# MCXN947_cm33_core0 register map
Vendor: nxp.com; File version: 1.0
CPU: CM33 r2p0, little endian, MPU, FPU, VTOR, 3 interrupt priority bits
Registers are 32-bit, read-write, reset 0x0 unless marked. A register's access mark holds for its fields unless they carry their own. Offsets are from the block's base; [hi:lo] are bit positions; lines under a group give offsets from that group; {n}, {i} and the like mark numbered series.

## SCT0 — SCT
Base 0x40091000
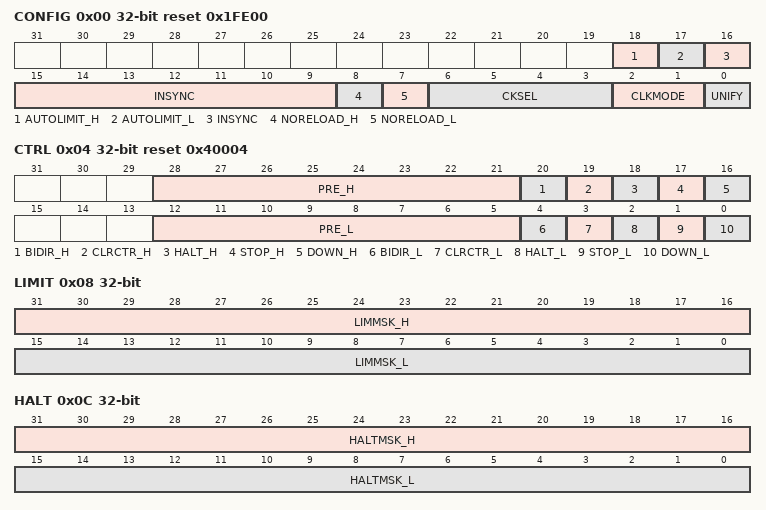
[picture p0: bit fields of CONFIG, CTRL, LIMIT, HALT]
0x00 CONFIG reset 0x1FE00 — SCT Configuration
  [18] AUTOLIMIT_H — Auto Limit Higher
    0=DISABLE (Disables); 1=ENABLE (Enables)
  [17] AUTOLIMIT_L — Auto Limit Lower
    0=DISABLE (Disables); 1=ENABLE (Enables)
  [16:9] INSYNC — Input Synchronization
  [8] NORELOAD_H — No Reload Higher Match
    0=RELOAD_H (Reloaded); 1=NO_RELOAD_H (Not reloaded)
  [7] NORELOAD_L — No Reload Lower Match
    0=RELOAD (Reloaded); 1=NO_RELOAD (Not reloaded)
  [6:3] CKSEL — SCT Clock Select
    0=INPUT_0_RISING_EDGES (Rising edges on input 0); 1=INPUT_0_FALLING_EDGES (Falling edges on input 0); 2=INPUT_1_RISING_EDGES (Rising edges on input 1); 3=INPUT_1_FALLING_EDGES (Falling edges on input 1); 4=INPUT_2_RISING_EDGES (Rising edges on input 2); 5=INPUT_2_FALLING_EDGES (Falling edges on input 2); 6=INPUT_3_RISING_EDGES (Rising edges on input 3); 7=INPUT_3_FALLING_EDGES (Falling edges on input 3); 8=INPUT_4_RISING_EDGES (Rising edges on input 4); 9=INPUT_4_FALLING_EDGES (Falling edges on input 4); 10=INPUT_5_RISING_EDGES (Rising edges on input 5); 11=INPUT_5_FALLING_EDGES (Falling edges on input 5); 12=INPUT_6_RISING_EDGES (Rising edges on input 6); 13=INPUT_6_FALLING_EDGES (Falling edges on input 6); 14=INPUT_7_RISING_EDGES (Rising edges on input 7); 15=INPUT_7_FALLING_EDGES (Falling edges on input 7)
  [2:1] CLKMODE — SCT Clock Mode
    0=SYSTEM_CLOCK_MODE; 1=SAMPLED_SYSTEM_CLOCK_MODE; 2=SCT_INPUT_CLOCK_MODE; 3=ASYNCHRONOUS_MODE
  [0] UNIFY — SCT Operation
    0=DUAL_COUNTER (Dual counters, COUNTER_L and COUNTER_H); 1=UNIFIED_COUNTER
0x04 CTRL reset 0x40004 — SCT Control
  [28:21] PRE_H — Prescaler for High Counter
  [20] BIDIR_H — Bidirectional Select High
    0=UP; 1=UP_DOWN
  [19] CLRCTR_H — Clear Counter High
  [18] HALT_H — Halt Counter High
    0=DISABLE; 1=ENABLE
  [17] STOP_H — Stop Counter High
    0=DISABLE (Disabled); 1=ENABLE (Enabled)
  [16] DOWN_H — Down Counter High
    0=UP; 1=DOWN
  [12:5] PRE_L — Prescaler for Low Counter
  [4] BIDIR_L — Bidirectional Select Low
    0=UP; 1=UP_DOWN
  [3] CLRCTR_L — Clear Counter Low
  [2] HALT_L — Halt Counter Low
    0=DISABLE (Disabled); 1=ENABLE (Enabled)
  [1] STOP_L — Stop Counter Low
    0=DISABLE (Disabled); 1=ENABLE (Enabled)
  [0] DOWN_L — Down Counter Low
    0=UP; 1=DOWN
0x08 LIMIT — SCT Limit Event Select
  [31:16] LIMMSK_H — Limit Event Counter High
  [15:0] LIMMSK_L — Limit Event Counter Low
0x0C HALT — Halt Event Select
  [31:16] HALTMSK_H — Halt Event High
  [15:0] HALTMSK_L — Halt Event Low
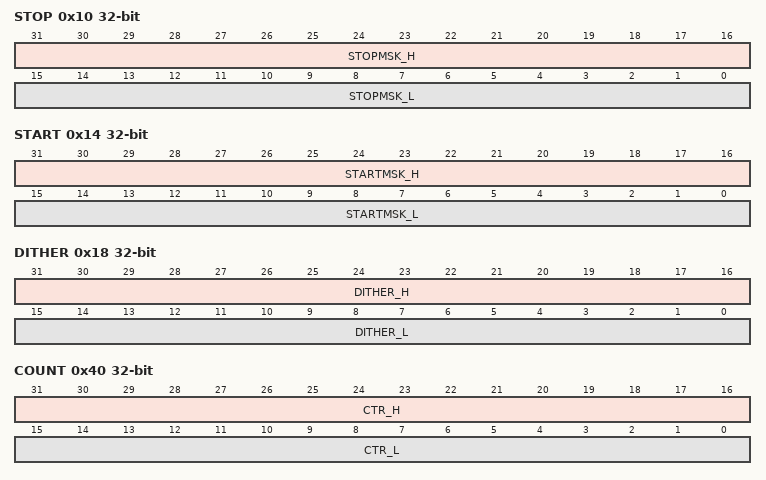
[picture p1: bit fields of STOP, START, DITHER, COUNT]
0x10 STOP — Stop Event Select
  [31:16] STOPMSK_H — Stop Event High
  [15:0] STOPMSK_L — Stop Event Low
0x14 START — Start Event Select
  [31:16] STARTMSK_H — Start Event High
  [15:0] STARTMSK_L — Start Event Low
0x18 DITHER — Dither Condition
  [31:16] DITHER_H — Dither High
  [15:0] DITHER_L — Dither Low
0x40 COUNT — Counter Value
  [31:16] CTR_H — Counter High
  [15:0] CTR_L — Counter Low
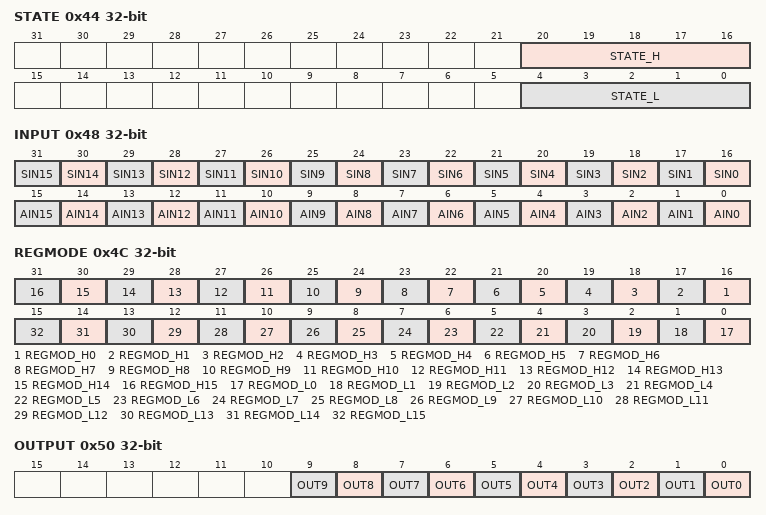
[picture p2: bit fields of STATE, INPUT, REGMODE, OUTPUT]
0x44 STATE — State Variable
  [20:16] STATE_H — State Variable High
  [4:0] STATE_L — State Variable Low
0x48 INPUT ro — Input State
  [n+16] SIN{n} (n=0..15) — Input {n} state
  [n] AIN{n} (n=0..15) — Input {n} state
0x4C REGMODE — Match and Capture Register Mode
  [all] fields
    0=MATCH; 1=CAPTURE
  [n+16] REGMOD_H{n} (n=0..15) — Register Mode High
  [n] REGMOD_L{n} (n=0..15) — Register Mode Low
0x50 OUTPUT — Output State
  [all] fields
    0=LOW (Forces the corresponding output low); 1=HIGH (Forces the corresponding output high)
  [n] OUT{n} (n=0..9) — Output Low and High
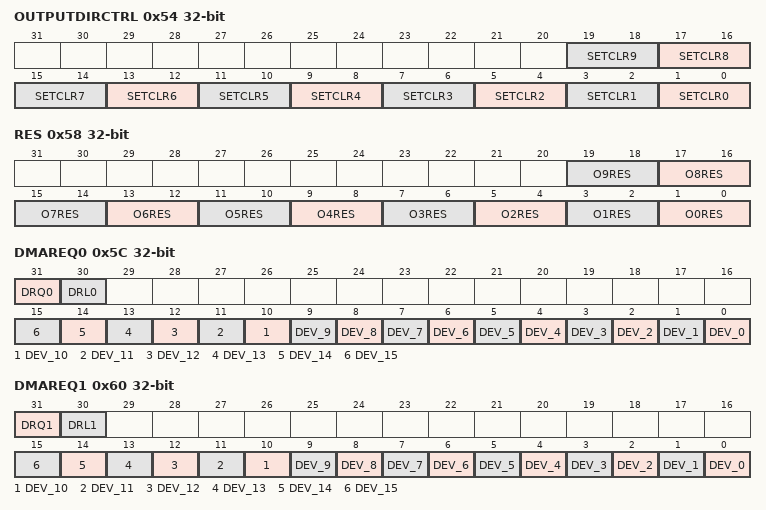
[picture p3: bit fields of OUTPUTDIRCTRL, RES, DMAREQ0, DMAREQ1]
0x54 OUTPUTDIRCTRL — Output Counter Direction Control
  [all] fields
    0=INDEPENDENT (Not dependent on the direction of any counter); 1=L_REVERSED (Reversed when counter L or the unified counter is counting down); 2=H_REVERSED (Reversed when counter H is counting down (do not use this value when CONFIG[UNIFY] = 1))
  [2n+1:2n] SETCLR{n} (n=0..9) — Set and Clear Operation on Output
0x58 RES — Output Conflict Resolution
  [all] fields
    0=NO_CHANGE; 1=SET (Set output (or clear, based on OUTPUTDIRCTRL[SETCLRn])); 2=CLEAR (Clear output (or set, based on OUTPUTDIRCTRL[SETCLRn])); 3=TOGGLE_OUTPUT
  [2n+1:2n] O{n}RES (n=0..9) — Output Resolution
0x5C DMAREQ0 — DMA Request 0
  [31] DRQ0 ro — DMA Request 0 State
  [30] DRL0 — DMA Request Low 0
  [n] DEV_{n} (n=0..15) — DMA Request Event
0x60 DMAREQ1 — DMA Request 1
  [31] DRQ1 ro — DMA Request 1 State
  [30] DRL1 — DMA Request Low 1
  [n] DEV_{n} (n=0..15) — DMA Request Event
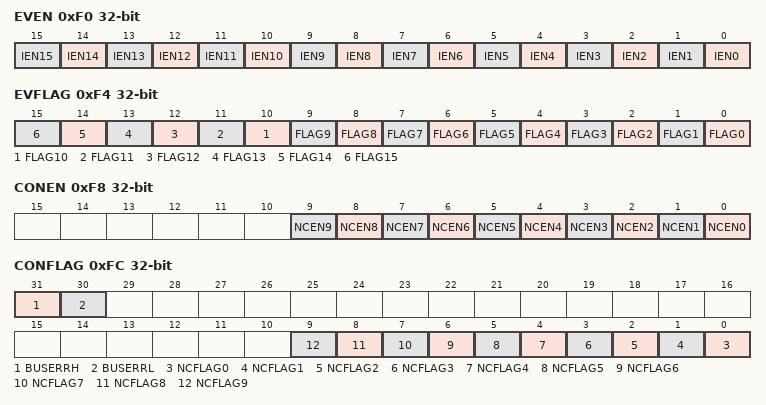
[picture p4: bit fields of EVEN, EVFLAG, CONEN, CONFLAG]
0xF0 EVEN — Event Interrupt Enable
  [all] fields
    0=DISABLE (Disables); 1=ENABLE (Enables)
  [n] IEN{n} (n=0..15) — Event Interrupt Enable
0xF4 EVFLAG — Event Flag
  [all] fields
    0=NO_FLAG; 1=FLAG (Event n flag)
  [n] FLAG{n} (n=0..15) — Event Flag
0xF8 CONEN — Conflict Interrupt Enable
  [all] fields
    0=NO_INTERRUPT; 1=INTERRUPT
  [n] NCEN{n} (n=0..9) — No Change Conflict Event and Interrupt Enable
0xFC CONFLAG — Conflict Flag
  [31] BUSERRH — Bus Error High
  [30] BUSERRL — Bus Error Low or Unified
  [n] NCFLAG{n} (n=0..9) — No Change Conflict Event Flag
    0=NO_NC_CONFLICT (Did not occur); 1=NC_CONFLICT (Occurred)
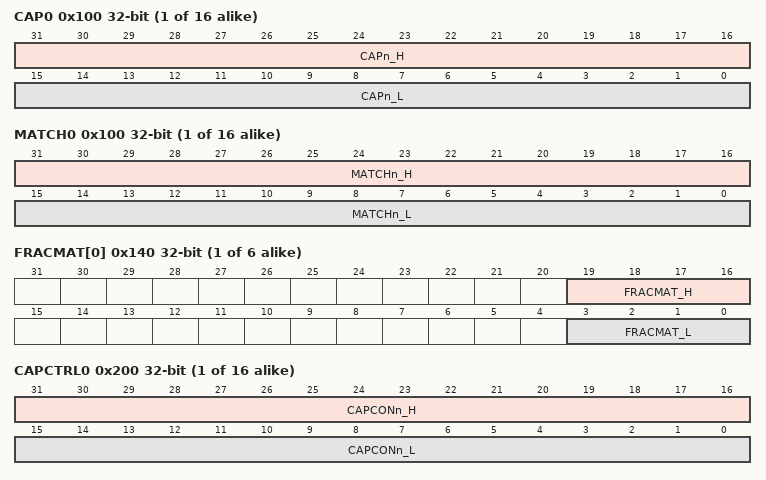
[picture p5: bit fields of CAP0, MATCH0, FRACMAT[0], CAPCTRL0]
{0x100+4i} CAP{i} (CAP_MATCH view) (i=0..15) — Capture Value
  [31:16] CAPn_H — Capture High
  [15:0] CAPn_L — Capture Low
{0x100+4i} MATCH{i} (CAP_MATCH view) (i=0..15) — Match Value
  [31:16] MATCHn_H — Match High
  [15:0] MATCHn_L — Match Low
{0x140+4i} FRACMAT[{i}] (i=0..5) — Fractional Match
  [19:16] FRACMAT_H — Fractional Match High
  [3:0] FRACMAT_L — Fractional Match Low
{0x200+4i} CAPCTRL{i} (CAPCTRL_MATCHREL view) (i=0..15) — Capture Control
  [31:16] CAPCONn_H — Capture Control High
  [15:0] CAPCONn_L — Capture Control Low
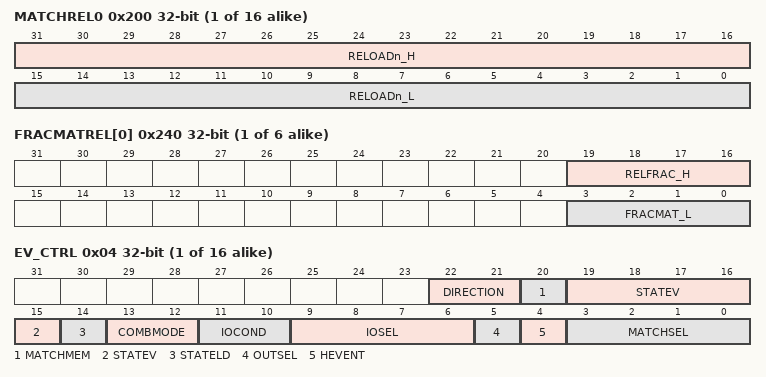
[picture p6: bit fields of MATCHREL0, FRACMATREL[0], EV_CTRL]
{0x200+4i} MATCHREL{i} (CAPCTRL_MATCHREL view) (i=0..15) — Match Reload Value
  [31:16] RELOADn_H — Reload High
  [15:0] RELOADn_L — Reload Low
{0x240+4i} FRACMATREL[{i}] (i=0..5) — Fractional Match Reload
  [19:16] RELFRAC_H — Reload Fractional Match High
  [3:0] FRACMAT_L — Reload Fractional Match Low
{0x300+8i} EVENT[{i}] (i=0..15) group
  0x00 EV_STATE (reset mask 0xFFFF) — Event n State
    [31:0] STATEMSKn — Event State Mask
  0x04 EV_CTRL — Event n Control
    [22:21] DIRECTION
      0=DIRECTION_INDEPENDENT (Direction independent (event triggered regardless of the count direction)); 1=COUNTING_UP (Counting up (event triggered only during up-counting when CTRL[BIDIR] = 1)); 2=COUNTING_DOWN (Counting down (event triggered only during down-counting when CTRL[BIDIR] = 1))
    [20] MATCHMEM
    [19:15] STATEV — State Value
    [14] STATELD — State Load
      0=ADD (Value of STATEV added to that of STATE (the carry out is ignored)); 1=LOAD (Value of STATEV loaded into that of STATE)
    [13:12] COMBMODE — Combination Mode
      0=OR (OR (the event occurs when either the specified match or I/O condition occurs)); 1=MATCH (MATCH (uses the specified match only)); 2=IO (IO (uses the specified I/O condition only)); 3=AND (AND (the event occurs when the specified match and I/O condition occur simultaneously))
    [11:10] IOCOND — Input or Output Condition
      0=LOW; 1=RISE; 2=FALL; 3=HIGH
    [9:6] IOSEL — Input or Output Signal Select
    [5] OUTSEL — Input and Output Select
      0=INPUT (Inputs); 1=OUTPUT (Outputs)
    [4] HEVENT — High Event
      0=L_COUNTER (Low counter (selects the L state and the L match register that the MATCHSEL field specifies)); 1=H_COUNTER (High counter (selects the H state and the H match register that the MATCHSEL field specifies))
    [3:0] MATCHSEL — Match Select
{0x500+8i} OUT[{i}] (i=0..9) group
  0x00 OUT_SET — Output n Set
    [15:0] SET — Set Output
  0x04 OUT_CLR — Output n Clear
    [15:0] CLR — Clear Output
